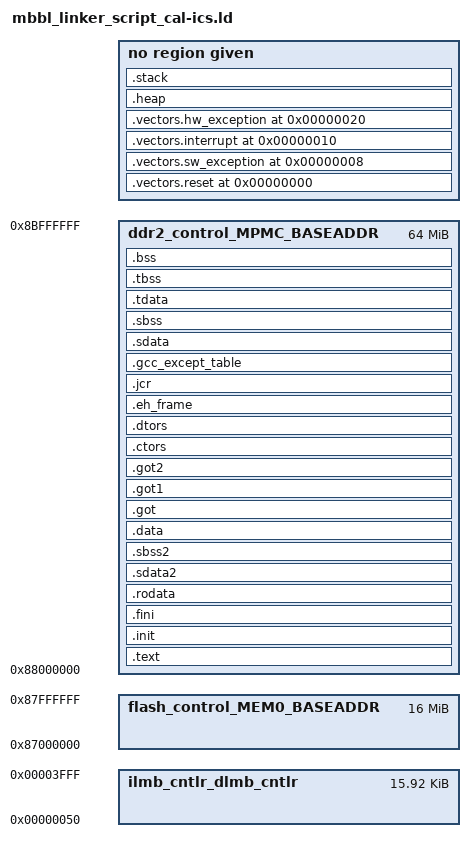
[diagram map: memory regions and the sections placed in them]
/*******************************************************************/
/*                                                                 */
/* This file is automatically generated by linker script generator.*/
/*                                                                 */
/* Version: Xilinx EDK 13.1 EDK_O.40d                                */
/*                                                                 */
/* Copyright (c) 2010 Xilinx, Inc.  All rights reserved.           */
/*                                                                 */
/* Description : MicroBlaze Linker Script                          */
/*                                                                 */
/*******************************************************************/

_STACK_SIZE = DEFINED(_STACK_SIZE) ? _STACK_SIZE : 0x400;
_HEAP_SIZE = DEFINED(_HEAP_SIZE) ? _HEAP_SIZE : 0x18000;
_EXEC_SIZE = DEFINED(_EXEC_SIZE) ? _EXEC_SIZE : 0x18000;

/* Define Memories in the system */

MEMORY
{
   ilmb_cntlr_dlmb_cntlr : ORIGIN = 0x00000050, LENGTH = 0x00003FB0
   flash_control_MEM0_BASEADDR : ORIGIN = 0x87000000, LENGTH = 0x01000000
   ddr2_control_MPMC_BASEADDR : ORIGIN = 0x88000000, LENGTH = 0x04000000
}

/* End of usable memory -- use for stack and heap */

DDR2_END = 0x8c000000;

/* Specify the default entry point to the program */

ENTRY(_start)

/* Define the sections, and where they are mapped in memory */

SECTIONS
{
.vectors.reset 0x00000000 : {
   *(.vectors.reset)
} 

.vectors.sw_exception 0x00000008 : {
   *(.vectors.sw_exception)
} 

.vectors.interrupt 0x00000010 : {
   *(.vectors.interrupt)
} 

.vectors.hw_exception 0x00000020 : {
   *(.vectors.hw_exception)
} 

.text DDR2_END - _STACK_SIZE - _HEAP_SIZE - _EXEC_SIZE : {
   *(.text)
   *(.text.*)
   *(.gnu.linkonce.t.*)
} >  ddr2_control_MPMC_BASEADDR

.init : {
   KEEP (*(.init))
} > ddr2_control_MPMC_BASEADDR

.fini : {
   KEEP (*(.fini))
} > ddr2_control_MPMC_BASEADDR

.rodata : {
   __rodata_start = .;
   *(.rodata)
   *(.rodata.*)
   *(.gnu.linkonce.r.*)
   __rodata_end = .;
} > ddr2_control_MPMC_BASEADDR

.sdata2 : {
   . = ALIGN(8);
   __sdata2_start = .;
   *(.sdata2)
   *(.sdata2.*)
   *(.gnu.linkonce.s2.*)
   . = ALIGN(8);
   __sdata2_end = .;
} > ddr2_control_MPMC_BASEADDR

.sbss2 : {
   __sbss2_start = .;
   *(.sbss2)
   *(.sbss2.*)
   *(.gnu.linkonce.sb2.*)
   __sbss2_end = .;
} > ddr2_control_MPMC_BASEADDR

.data : {
   . = ALIGN(4);
   __data_start = .;
   *(.data)
   *(.data.*)
   *(.gnu.linkonce.d.*)
   __data_end = .;
} > ddr2_control_MPMC_BASEADDR

.got : {
   *(.got)
} > ddr2_control_MPMC_BASEADDR

.got1 : {
   *(.got1)
} > ddr2_control_MPMC_BASEADDR

.got2 : {
   *(.got2)
} > ddr2_control_MPMC_BASEADDR

.ctors : {
   __CTOR_LIST__ = .;
   ___CTORS_LIST___ = .;
   KEEP (*crtbegin.o(.ctors))
   KEEP (*(EXCLUDE_FILE(*crtend.o) .ctors))
   KEEP (*(SORT(.ctors.*)))
   KEEP (*(.ctors))
   __CTOR_END__ = .;
   ___CTORS_END___ = .;
} > ddr2_control_MPMC_BASEADDR

.dtors : {
   __DTOR_LIST__ = .;
   ___DTORS_LIST___ = .;
   KEEP (*crtbegin.o(.dtors))
   KEEP (*(EXCLUDE_FILE(*crtend.o) .dtors))
   KEEP (*(SORT(.dtors.*)))
   KEEP (*(.dtors))
   __DTOR_END__ = .;
   ___DTORS_END___ = .;
} > ddr2_control_MPMC_BASEADDR

.eh_frame : {
   *(.eh_frame)
} > ddr2_control_MPMC_BASEADDR

.jcr : {
   *(.jcr)
} > ddr2_control_MPMC_BASEADDR

.gcc_except_table : {
   *(.gcc_except_table)
} > ddr2_control_MPMC_BASEADDR

.sdata : {
   . = ALIGN(8);
   __sdata_start = .;
   *(.sdata)
   *(.sdata.*)
   *(.gnu.linkonce.s.*)
   __sdata_end = .;
} > ddr2_control_MPMC_BASEADDR

.sbss : {
   . = ALIGN(4);
   __sbss_start = .;
   *(.sbss)
   *(.sbss.*)
   *(.gnu.linkonce.sb.*)
   . = ALIGN(8);
   __sbss_end = .;
} > ddr2_control_MPMC_BASEADDR

.tdata : {
   __tdata_start = .;
   *(.tdata)
   *(.tdata.*)
   *(.gnu.linkonce.td.*)
   __tdata_end = .;
} > ddr2_control_MPMC_BASEADDR

.tbss : {
   __tbss_start = .;
   *(.tbss)
   *(.tbss.*)
   *(.gnu.linkonce.tb.*)
   __tbss_end = .;
} > ddr2_control_MPMC_BASEADDR

.bss : {
   . = ALIGN(4);
   __bss_start = .;
   *(.bss)
   *(.bss.*)
   *(.gnu.linkonce.b.*)
   *(COMMON)
   . = ALIGN(4);
   __bss_end = .;
} > ddr2_control_MPMC_BASEADDR

_SDA_BASE_ = __sdata_start + ((__sbss_end - __sdata_start) / 2 );

_SDA2_BASE_ = __sdata2_start + ((__sbss2_end - __sdata2_start) / 2 );

/* Generate Stack and Heap definitions */

.heap : {
   _heap = DDR2_END - _STACK_SIZE - _HEAP_SIZE;
   _heap_start = _heap;
   _heap_end = _heap_start + _HEAP_SIZE;
}

.stack : {
   _stack_end = DDR2_END - _STACK_SIZE;
   _stack = DDR2_END;
   __stack = _stack;
}

}
